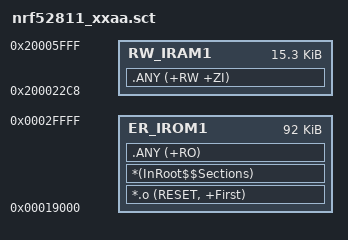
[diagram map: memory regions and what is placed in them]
; *************************************************************
; *** Scatter-Loading Description File generated by uVision ***
; *************************************************************

LR_IROM1 0x00019000 0x00017000  {    ; load region size_region
  ER_IROM1 0x00019000 0x00017000  {  ; load address = execution address
   *.o (RESET, +First)
   *(InRoot$$Sections)
   .ANY (+RO)
  }
  RW_IRAM1 0x200022C8 0x00003D38  {  ; RW data
   .ANY (+RW +ZI)
  }
}

